# STM32H553xx register map
File version: 1.0
Registers are 32-bit, read-write, reset 0x0 unless marked. A register's access mark holds for its fields unless they carry their own. Offsets are from the block's base; [hi:lo] are bit positions; {n}, {i} and the like mark numbered series.

## EXTI — Asynch Interrupt/Event Controller (EXTI)
Base 0x44022000
Same registers: EXTI_S 0x54022000
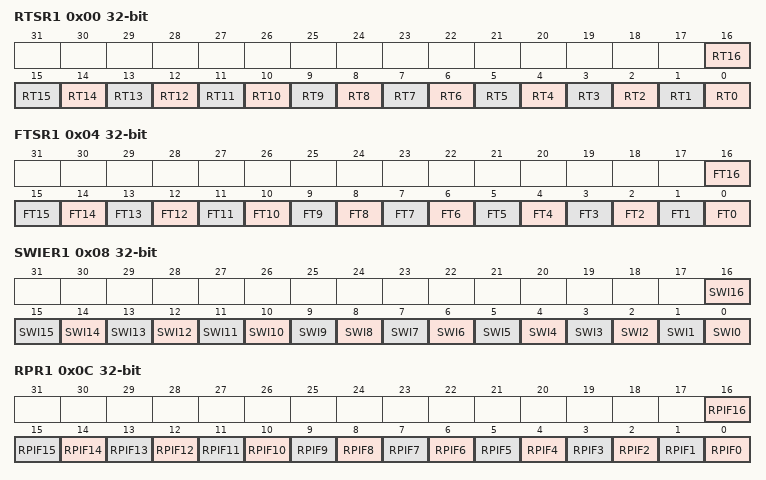
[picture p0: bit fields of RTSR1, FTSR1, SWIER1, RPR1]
0x00 RTSR1 — EXTI Rising Trigger Selection Register 1
  [n] RT{n} (n=0..16) — Rising trigger configuration for input line {n}
0x04 FTSR1 — EXTI Falling Trigger Selection Register 1
  [n] FT{n} (n=0..16) — Falling trigger configuration for input line {n}
0x08 SWIER1 — EXTI Software Interrupt event Register 1
  [n] SWI{n} (n=0..16) — Software Interrupt on line {n}
0x0C RPR1 — EXTI Rising Pending Register 1
  [n] RPIF{n} (n=0..16) — Rising Pending Interrupt Flag on line {n}
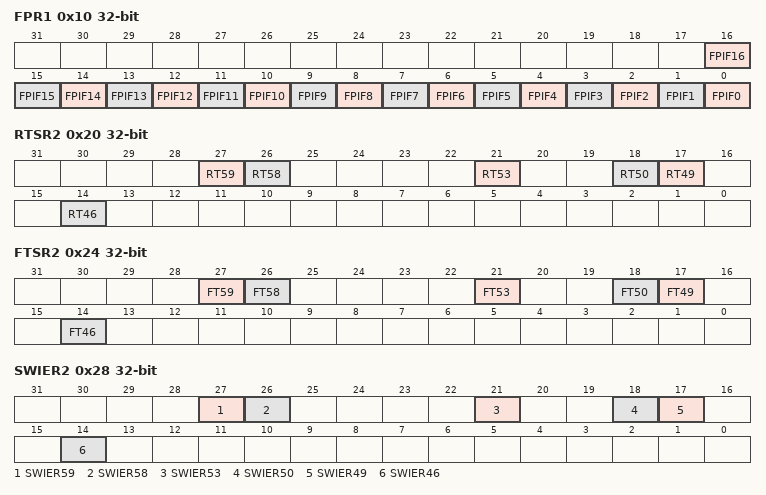
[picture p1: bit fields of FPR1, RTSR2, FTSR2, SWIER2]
0x10 FPR1 — EXTI Falling Pending Register 1
  [n] FPIF{n} (n=0..16) — Falling Pending Interrupt Flag on line {n}
0x14 SECCFGR1 — EXTI Security Configuration Register 1
0x18 PRIVCFGR1 — EXTI Privilege Configuration Register 1
0x20 RTSR2 — EXTI Rising Trigger Selection Register 2
  [27] RT59 — Rising trigger event configuration bit of line 59
  [26] RT58 — Rising trigger event configuration bit of line 58
  [21] RT53 — Rising trigger event configuration bit of line 53
  [18] RT50 — Rising trigger event configuration bit of line 50
  [17] RT49 — Rising trigger event configuration bit of line 49
  [14] RT46 — Rising trigger event configuration bit of line 46
0x24 FTSR2 — EXTI Falling Trigger Selection Register 2
  [27] FT59 — Falling trigger event configuration bit of line 59
  [26] FT58 — Falling trigger event configuration bit of line 58
  [21] FT53 — Falling trigger event configuration bit of line 53
  [18] FT50 — Falling trigger event configuration bit of line 50
  [17] FT49 — Falling trigger event configuration bit of line 49
  [14] FT46 — Falling trigger event configuration bit of line 46
0x28 SWIER2 — EXTI Software Interrupt event Register 2
  [27] SWIER59 — Software Interrupt on line 59
  [26] SWIER58 — Software Interrupt on line 58
  [21] SWIER53 — Software Interrupt on line 53
  [18] SWIER50 — Software Interrupt on line 50
  [17] SWIER49 — Software Interrupt on line 49
  [14] SWIER46 — Software Interrupt on line 46
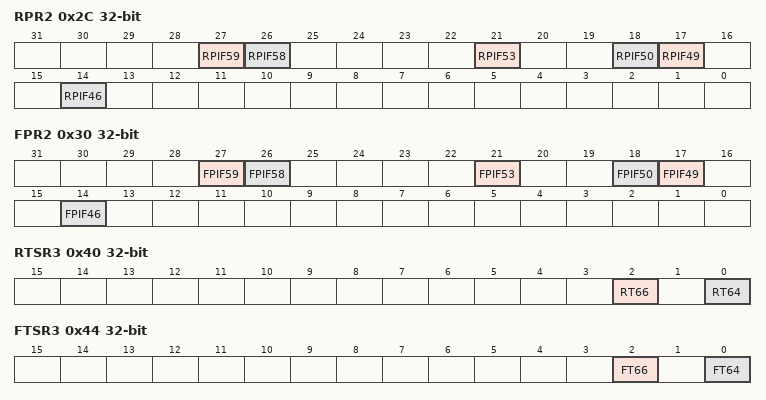
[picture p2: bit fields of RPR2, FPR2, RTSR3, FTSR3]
0x2C RPR2 — EXTI Rising Pending Register 2
  [27] RPIF59 — Rising pending edge configuration bit of line 59
  [26] RPIF58 — Rising pending edge configuration bit of line 58
  [21] RPIF53 — Rising pending edge configuration bit of line 53
  [18] RPIF50 — Rising pending edge configuration bit of line 50
  [17] RPIF49 — Rising pending edge configuration bit of line 49
  [14] RPIF46 — Rising pending edge configuration bit of line 46
0x30 FPR2 — EXTI Falling Pending Register 2
  [27] FPIF59 — Rising falling edge configuration bit of line 59
  [26] FPIF58 — Rising falling edge configuration bit of line 58
  [21] FPIF53 — Rising falling edge configuration bit of line 53
  [18] FPIF50 — Rising falling edge configuration bit of line 50
  [17] FPIF49 — Rising falling edge configuration bit of line 49
  [14] FPIF46 — Rising falling edge configuration bit of line 46
0x34 SECCFGR2 — EXTI Security Configuration Register 2
0x38 PRIVCFGR2 — EXTI Privilege Configuration Register 2
0x40 RTSR3 — EXTI Rising Trigger Selection Register 3
  [2] RT66 — Rising trigger event configuration bit of line 59
  [0] RT64 — Rising trigger event configuration bit of line 58
0x44 FTSR3 — EXTI Falling Trigger Selection Register 3
  [2] FT66 — Falling trigger event configuration bit of line 66
  [0] FT64 — Falling trigger event configuration bit of line 64
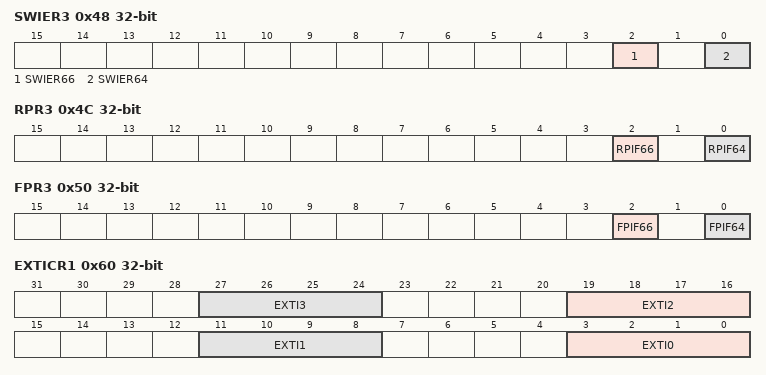
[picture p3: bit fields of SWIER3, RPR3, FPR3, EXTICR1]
0x48 SWIER3 — EXTI Software Interrupt event Register 3
  [2] SWIER66 — Software Interrupt on line 66
  [0] SWIER64 — Software Interrupt on line 64
0x4C RPR3 — EXTI Rising Pending Register 3
  [2] RPIF66 — Rising pending edge configuration bit of line 66
  [0] RPIF64 — Rising pending edge configuration bit of line 64
0x50 FPR3 — EXTI Falling Pending Register 3
  [2] FPIF66 — Rising falling edge configuration bit of line 66
  [0] FPIF64 — Rising falling edge configuration bit of line 64
0x54 SECCFGR3 — EXTI Security Configuration Register 3
0x58 PRIVCFGR3 — EXTI Privilege Configuration Register 3
0x60 EXTICR1 — EXIT External Interrupt Configuration Register, 0x60 -- 0x6C
  [8n+3:8n] EXTI{n} (n=0..3) — EXTI {n} configuration
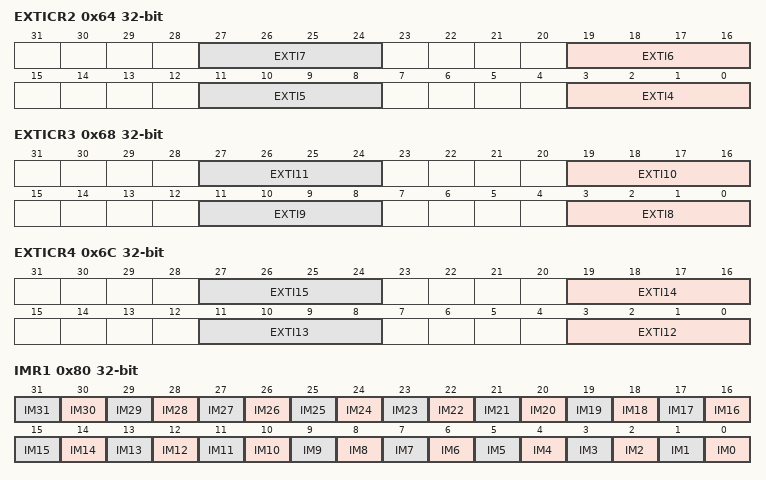
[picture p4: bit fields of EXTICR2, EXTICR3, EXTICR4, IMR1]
0x64 EXTICR2 — EXIT External Interrupt Configuration Register, 0x60 -- 0x6C
  [8n-29:8n-32] EXTI{n} (n=4..7) — EXTI {n} configuration
0x68 EXTICR3 — EXIT External Interrupt Configuration Register, 0x60 -- 0x6C
  [8n-61:8n-64] EXTI{n} (n=8..11) — EXTI {n} configuration
0x6C EXTICR4 — EXIT External Interrupt Configuration Register, 0x60 -- 0x6C
  [8n-93:8n-96] EXTI{n} (n=12..15) — EXTI {n} configuration
0x70 LOCKR — EXTI Lock Register
  [0] LOCK — Lock Mask
0x80 IMR1 — EXTI Interrupt Mask Register 1
  [n] IM{n} (n=0..31) — Interrupt Mask on line {n}
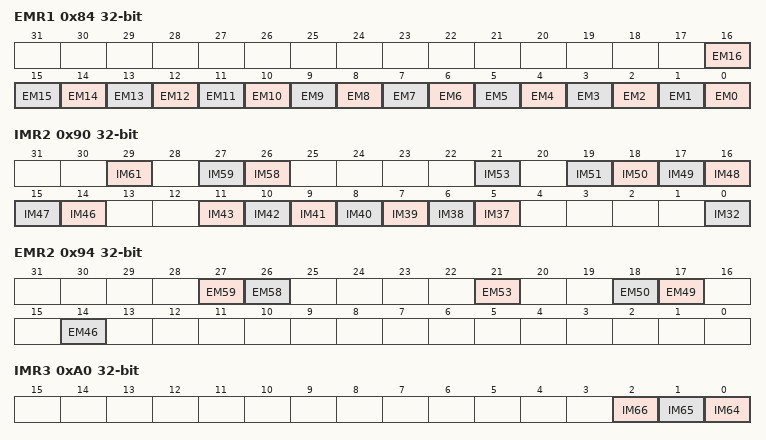
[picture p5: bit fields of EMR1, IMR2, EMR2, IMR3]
0x84 EMR1 — EXTI Event Mask Register 1
  [n] EM{n} (n=0..16) — Event Mask on line {n}
0x90 IMR2 — EXTI Interrupt Mask Register 2
  [29] IM61 — Interrupt Mask on line 61
  [27] IM59 — Interrupt Mask on line 59
  [26] IM58 — Interrupt Mask on line 58
  [21] IM53 — Interrupt Mask on line 53
  [n-32] IM{n} (n=46..51) — Interrupt Mask on line {n}
  [n-32] IM{n} (n=37..43) — Interrupt Mask on line {n}
  [0] IM32 — Interrupt Mask on line 32
0x94 EMR2 — EXTI Event Mask Register 2
  [27] EM59 — Event Mask on line 59
  [26] EM58 — Event Mask on line 58
  [21] EM53 — Event Mask on line 53
  [18] EM50 — Event Mask on line 50
  [17] EM49 — Event Mask on line 49
  [14] EM46 — Event Mask on line 46
0xA0 IMR3 — EXTI Interrupt Mask Register 3
  [2] IM66 — Interrupt Mask on line 66
  [1] IM65 — Interrupt Mask on line 65
  [0] IM64 — Interrupt Mask on line 64
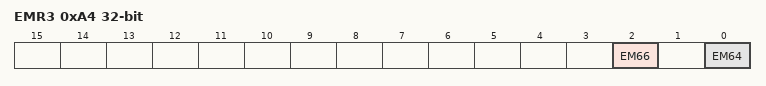
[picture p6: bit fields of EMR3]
0xA4 EMR3 — EXTI Event Mask Register 3
  [2] EM66 — Event Mask on line 66
  [0] EM64 — Event Mask on line 64
